# max32570 register map
Vendor: Maxim-Integrated; Series: ARMCM4; File version: 1.0
CPU: CM4 r2p1, little endian, MPU, FPU, 3 interrupt priority bits
Registers are 32-bit, read-write, reset 0x0 unless marked. A register's access mark holds for its fields unless they carry their own. Offsets are from the block's base; [hi:lo] are bit positions.

## SPIXFC_FIFO — SPI XiP Master Controller FIFO.
Base 0x400BC000
0x00 TX_8 8-bit — SPI TX FIFO 8-Bit Write
0x00 TX_16 16-bit (alternate view of TX_8) — SPI TX FIFO 16-Bit Write
0x00 TX_32 (alternate view of TX_8) — SPI TX FIFO 32-Bit Write
0x04 RX_8 8-bit — SPI RX FIFO 8-Bit Access
0x04 RX_16 16-bit (alternate view of RX_8) — SPI RX FIFO 16-Bit Access
0x04 RX_32 (alternate view of RX_8) — SPI RX FIFO 32-Bit Access

## SRCC — SPIX Cache Controller Registers.
Base 0x40033000
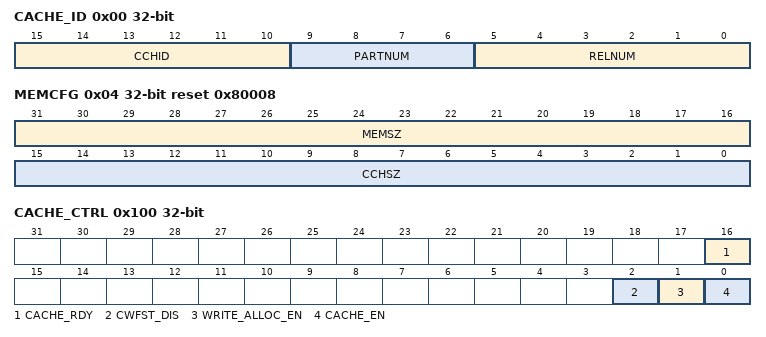
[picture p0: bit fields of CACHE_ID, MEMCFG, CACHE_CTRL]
0x00 CACHE_ID ro
  [15:10] CCHID — Cache ID. This field reflects the value of the C_ID_CACHEID configuration parameter.
  [9:6] PARTNUM — Part Number. This field reflects the value of C_ID_PART_NUMBER configuration parameter.
  [5:0] RELNUM — Release Number. Identifies the RTL release version.
0x04 MEMCFG ro reset 0x80008 — Memory Configuration Register.
  [31:16] MEMSZ — Main Memory Size. Indicates the total size, in units of 128 Kbytes, of code memory accessible to the cache controller.
  [15:0] CCHSZ — Cache Size. Indicates total size in Kbytes of cache.
0x100 CACHE_CTRL — Cache Control and Status Register.
  [16] CACHE_RDY — Cache Ready flag. Cleared by hardware when at any time the cache as a whole is invalidated (including a system reset). When this bit is 0, the cache is effectively in bypass mode (instruction fetches will come from main memory or from the line fill buffer). Set by hardware when the invalidate operation is complete and the cache is ready.
    0=notReady; 1=ready
  [2] CWFST_DIS — Critical word first and streaming disable. This bit only writeable while the cache is disabled.
    1=dis (Critical word first and streaming disabled.); 0=en (Critical word first and streaming enabled.)
  [1] WRITE_ALLOC_EN — Write Allocate Enable. This bit only writable while the cache is disabled.
    0=dis (Write-no-allocate.); 1=en (Write-allocate enabled.)
  [0] CACHE_EN — Cache Enable. Controls whether the cache is bypassed or is in use. Changing the state of this bit will cause the instruction cache to be flushed and its contents invalidated.
    0=dis (Cache Bypassed. Instruction data is stored in the line fill buffer but is not written to main cache memory array.); 1=en (Cache Enabled.)
0x700 INVALIDATE — Invalidate All Cache Contents. Any time this register location is written (regardless of the data value), the cache controller immediately begins invalidating the entire contents of the cache memory. The cache will be in bypass mode until the invalidate operation is complete. System software can examine the Cache Ready bit (CACHE_CTRL.CACHE_RDY) to determine when the invalidate operation is complete. Note that it is not necessary to disable the cache controller prior to beginning this operation. Reads from this register always return 0.
  [31:0] IA — Invalidate all cache contents.

## TMR0 — 32-bit reloadable timer that can be used for timing and event counting.
Base 0x40010000
Same registers: TMR1 0x40011000, TMR2 0x40012000, TMR3 0x40013000, TMR4 0x40014000, TMR5 0x40015000
0x00 CNT reset 0x1 — Count. This register stores the current timer count.
0x04 CMP reset 0xFFFF — Compare. This register stores the compare value, which is used to set the maximum count value to initiate a reload of the timer to 0x0001.
0x08 PWM — PWM. This register stores the value that is compared to the current timer count.
0x0C INTR write-1-clears — Clear Interrupt. Writing a value (0 or 1) to a bit in this register clears the associated interrupt.
  [0] IRQ — Clear Interrupt.
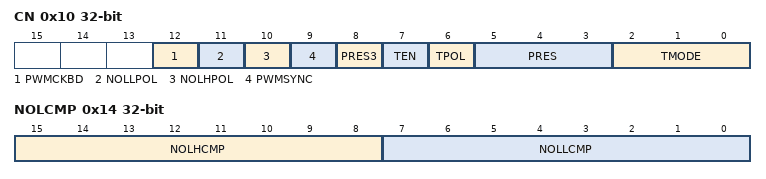
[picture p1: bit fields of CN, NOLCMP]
0x10 CN — Timer Control Register.
  [12] PWMCKBD — Timer PWM output 0A Mode Disable.
    1=dis (Disable.); 0=en (Enable.)
  [11] NOLLPOL — Timer PWM output 0A' polarity bit.
    0=dis (Disable.); 1=en (Enable.)
  [10] NOLHPOL — Timer PWM output 0A polarity bit.
    0=dis (Disable.); 1=en (Enable.)
  [9] PWMSYNC — Timer PWM Synchronization Mode Enable.
    0=dis (Disable.); 1=en (Enable.)
  [8] PRES3 — MSB of prescaler value.
  [7] TEN — Timer Enable.
    0=dis (Disable.); 1=en (Enable.)
  [6] TPOL — Timer input/output polarity bit.
    0=Active High; 1=Active Low
  [5:3] PRES — Prescaler. Set the Timer's prescaler value. The prescaler divides the PCLK input to the timer and sets the Timer's Count Clock, F_CNT_CLK = PCLK (HZ) /prescaler. The Timer's prescaler setting is a 4-bit value with pres3:pres[2:0].
    0=div1 (Divide by 1.); 1=div2 (Divide by 2.); 2=div4 (Divide by 4.); 3=div8 (Divide by 8.); 4=div16 (Divide by 16.); 5=div32 (Divide by 32.); 6=div64 (Divide by 64.); 7=div128 (Divide by 128.)
  [2:0] TMODE — Timer Mode.
    0=One Shot Mode; 1=Continuous Mode; 2=Counter Mode; 3=pwm (PWM Mode.); 4=Capture Mode; 5=Compare Mode; 6=Gated Mode; 7=Capture/Compare Mode
0x14 NOLCMP — Timer Non-Overlapping Compare Register.
  [15:8] NOLHCMP — Non-overlapping High Compare. The 8-bit timer count value of non-overlapping time between falling edge of PWM output 0A' and next rising edge of PWM output 0A.
  [7:0] NOLLCMP — Non-overlapping Low Compare. The 8-bit timer count value of non-overlapping time between falling edge of PWM output 0A and next rising edge of PWM output 0A'.
